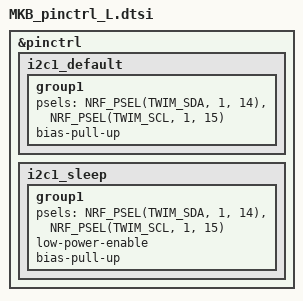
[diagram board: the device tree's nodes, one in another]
&pinctrl {    
    i2c1_default: i2c1_default {
        group1 {
            psels = <NRF_PSEL(TWIM_SDA, 1, 14)>,
                    <NRF_PSEL(TWIM_SCL, 1, 15)>;
            bias-pull-up;
        };
    };
      
    i2c1_sleep: i2c1_sleep {
        group1 {
            psels = <NRF_PSEL(TWIM_SDA, 1, 14)>,
                    <NRF_PSEL(TWIM_SCL, 1, 15)>;
            low-power-enable;
            bias-pull-up;
        };
    };
};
